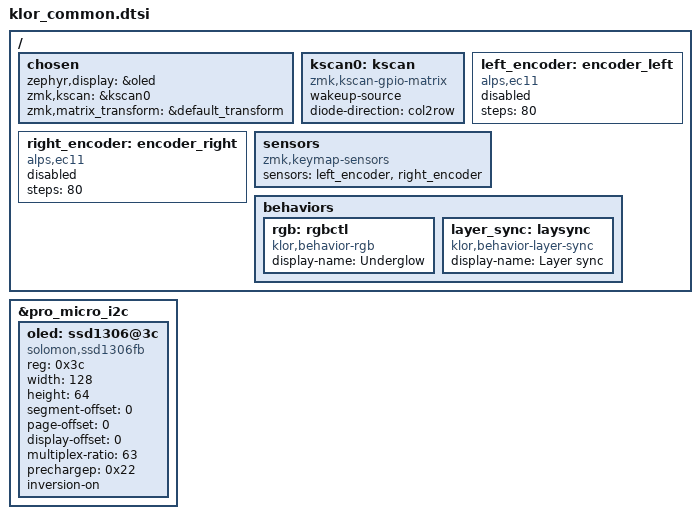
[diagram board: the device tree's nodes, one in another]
/*
 * Copyright (c) 2022 The ZMK Contributors
 *
 * SPDX-License-Identifier: MIT
 */

#include <dt-bindings/zmk/matrix_transform.h>

/ {
	chosen {
		zephyr,display = &oled;
		zmk,kscan = &kscan0;
		zmk,matrix_transform = &default_transform;
	};

	kscan0: kscan {
		compatible = "zmk,kscan-gpio-matrix";
		wakeup-source;

		diode-direction = "col2row";
	};

	/*
	 * steps = pulses per FULL ROTATION, which replaced the deprecated
	 * "resolution" (pulses per detent, which was 4 here). These are not the
	 * same units, so this is a conversion rather than a rename:
	 *
	 *   20 detents x 4 quadrature pulses = 80 pulses per rotation
	 *
	 * The result is identical to the old behaviour. In steps mode the driver
	 * reports degrees, so one detent is (4 * 360) / 80 = 18 degrees, and ZMK
	 * fires a behavior every 360 / CONFIG_ZMK_KEYMAP_SENSORS_DEFAULT_TRIGGERS_
	 * PER_ROTATION = 360 / 20 = 18 degrees. One detent, one trigger, as before.
	 *
	 * If these encoders turn out not to have 20 detents, override
	 * triggers-per-rotation on the sensors node rather than fiddling with
	 * steps -- steps describes the hardware, triggers-per-rotation describes
	 * how often you want the keymap to fire.
	 */
	left_encoder: encoder_left {
		compatible = "alps,ec11";
		steps = <80>;
		status = "disabled";
	};

	right_encoder: encoder_right {
		compatible = "alps,ec11";
		steps = <80>;
		status = "disabled";
	};

	sensors {
		compatible = "zmk,keymap-sensors";
		sensors = <&left_encoder &right_encoder>;
	};

	// TODO: RGB node(s)
};

&pro_micro_i2c {
	status = "okay";

	oled: ssd1306@3c {
		compatible = "solomon,ssd1306fb";
		reg = <0x3c>;
		width = <128>;
		height = <64>;
		segment-offset = <0>;
		page-offset = <0>;
		display-offset = <0>;
		multiplex-ratio = <63>;
		prechargep = <0x22>;
		inversion-on;
	};
};

/*
 * The on/off switch for the reactive underglow, implemented in
 * src/klor_rgb_behavior.c. It lives here rather than in the keymap's behaviors
 * block because it must exist on BOTH halves: the behavior is global-locality,
 * so the central forwards it over the split link and the peripheral resolves it
 * by name. A node defined only on the central would leave the right half's
 * strip stuck on.
 *
 * The binding comes from dts/bindings/behaviors/klor,behavior-rgb.yaml, found
 * because zephyr/module.yml sets dts_root.
 *
 * THE NODE NAME MUST BE 8 CHARACTERS OR FEWER. It is what travels over the
 * split link: the central sends DEVICE_DT_NAME(node) -- the node name, since
 * there is no label property -- and the peripheral looks the behavior up by
 * that string. The wire field is
 * char behavior_dev[ZMK_SPLIT_RUN_BEHAVIOR_DEV_LEN], and that length is 9, so
 * strlcpy silently keeps 8 characters plus a NUL.
 *
 * This already bit once. The node was called klor_rgb_control, which went out
 * as "klor_rgb", matched nothing on the peripheral, and produced a toggle that
 * worked perfectly on the left half and did nothing on the right -- because the
 * central invokes the behavior locally under its full, untruncated name. ZMK
 * hits the same wall and solves it the same way: its own global behavior is
 * "ext_power: extpower", the label long and the node name short, with the
 * comment "Behavior can be invoked on peripherals, so name must be <= 8
 * characters."
 *
 * Keep the label descriptive and the node name short.
 */
/ {
	behaviors {
		rgb: rgbctl {
			compatible = "klor,behavior-rgb";
			#binding-cells = <1>;
			display-name = "Underglow";
		};

		/*
		 * Not bound to any key. The central invokes it directly to tell the
		 * peripheral which layer is active, since the peripheral never runs
		 * the keymap and RUN_BEHAVIOR is the only downward channel that can
		 * carry a value. Node name kept short for the same 8-character reason
		 * as rgbctl above -- this one actually travels the link every time a
		 * layer changes.
		 */
		layer_sync: laysync {
			compatible = "klor,behavior-layer-sync";
			#binding-cells = <1>;
			display-name = "Layer sync";
		};
	};
};
